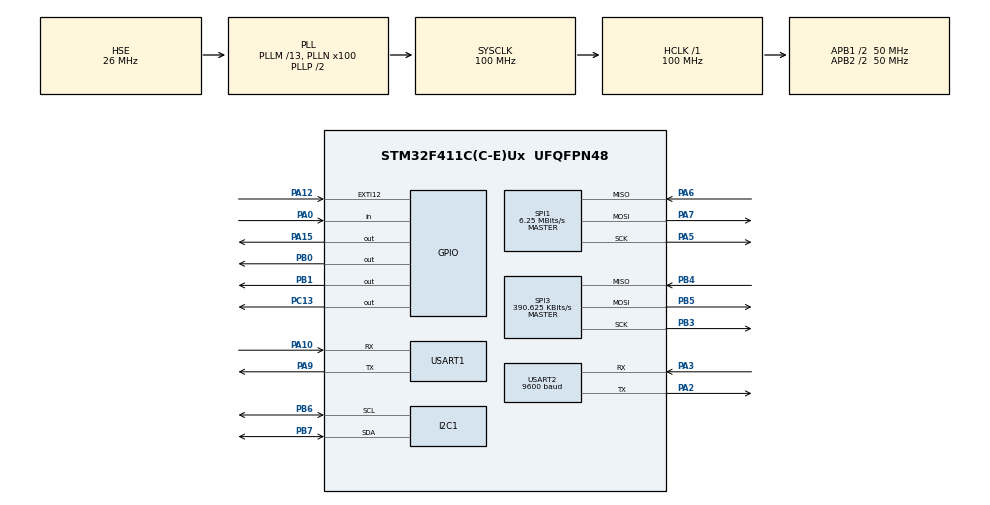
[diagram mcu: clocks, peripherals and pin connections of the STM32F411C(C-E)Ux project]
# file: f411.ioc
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Dma.Request0=USART2_RX
Dma.Request1=SPI3_TX
Dma.SPI3_TX.1.Direction=DMA_MEMORY_TO_PERIPH
Dma.SPI3_TX.1.FIFOMode=DMA_FIFOMODE_DISABLE
Dma.SPI3_TX.1.Instance=DMA1_Stream7
Dma.SPI3_TX.1.MemDataAlignment=DMA_MDATAALIGN_BYTE
Dma.SPI3_TX.1.MemInc=DMA_MINC_ENABLE
Dma.SPI3_TX.1.Mode=DMA_NORMAL
Dma.SPI3_TX.1.PeriphDataAlignment=DMA_PDATAALIGN_BYTE
Dma.SPI3_TX.1.PeriphInc=DMA_PINC_DISABLE
Dma.SPI3_TX.1.Priority=DMA_PRIORITY_MEDIUM
Dma.USART2_RX.0.Direction=DMA_PERIPH_TO_MEMORY
Dma.USART2_RX.0.FIFOMode=DMA_FIFOMODE_DISABLE
Dma.USART2_RX.0.Instance=DMA1_Stream5
Dma.USART2_RX.0.MemDataAlignment=DMA_MDATAALIGN_BYTE
Dma.USART2_RX.0.MemInc=DMA_MINC_ENABLE
Dma.USART2_RX.0.Mode=DMA_NORMAL
Dma.USART2_RX.0.PeriphDataAlignment=DMA_PDATAALIGN_BYTE
Dma.USART2_RX.0.PeriphInc=DMA_PINC_DISABLE
Dma.USART2_RX.0.Priority=DMA_PRIORITY_LOW
I2C1.I2C_Mode=I2C_Fast
Mcu.Family=STM32F4
Mcu.Name=STM32F411C(C-E)Ux
Mcu.Package=UFQFPN48
NVIC.DMA1_Stream5_IRQn=true\:0\:0\:false\:false\:true\:false\:true\:true
NVIC.DMA1_Stream7_IRQn=true\:0\:0\:false\:false\:true\:false\:true\:true
NVIC.EXTI15_10_IRQn=true\:0\:0\:false\:false\:true\:true\:true\:true
NVIC.PriorityGroup=NVIC_PRIORITYGROUP_4
NVIC.TIM3_IRQn=true\:0\:0\:false\:false\:true\:true\:true\:true
NVIC.USART2_IRQn=true\:0\:0\:false\:false\:true\:true\:true\:true
PA0-WKUP.Signal=GPIO_Input
PA10.Mode=Asynchronous
PA10.Signal=USART1_RX
PA12.GPIO_ModeDefaultEXTI=GPIO_MODE_IT_RISING
PA12.Signal=GPXTI12
PA13.Mode=Serial_Wire
PA13.Signal=SYS_JTMS-SWDIO
PA14.Mode=Serial_Wire
PA14.Signal=SYS_JTCK-SWCLK
PA15.GPIO_Speed=GPIO_SPEED_FREQ_VERY_HIGH
PA15.PinState=GPIO_PIN_SET
PA15.Signal=GPIO_Output
PA2.Mode=Asynchronous
PA2.Signal=USART2_TX
PA3.Mode=Asynchronous
PA3.Signal=USART2_RX
PA5.Mode=Full_Duplex_Master
PA5.Signal=SPI1_SCK
PA6.Mode=Full_Duplex_Master
PA6.Signal=SPI1_MISO
PA7.Mode=Full_Duplex_Master
PA7.Signal=SPI1_MOSI
PA9.Mode=Asynchronous
PA9.Signal=USART1_TX
PB0.Signal=GPIO_Output
PB1.Signal=GPIO_Output
PB3.Mode=Full_Duplex_Master
PB3.Signal=SPI3_SCK
PB4.Mode=Full_Duplex_Master
PB4.Signal=SPI3_MISO
PB5.Mode=Full_Duplex_Master
PB5.Signal=SPI3_MOSI
PB6.Mode=I2C
PB6.Signal=I2C1_SCL
PB7.Mode=I2C
PB7.Signal=I2C1_SDA
PC13-ANTI_TAMP.Signal=GPIO_Output
PH0\ -\ OSC_IN.Mode=HSE-External-Oscillator
PH0\ -\ OSC_IN.Signal=RCC_OSC_IN
PH1\ -\ OSC_OUT.Mode=HSE-External-Oscillator
PH1\ -\ OSC_OUT.Signal=RCC_OSC_OUT
ProjectManager.HeapSize=0x200
ProjectManager.StackSize=0x400
ProjectManager.TargetToolchain=STM32CubeIDE
RCC.48MHZClocksFreq_Value=50000000
RCC.AHBFreq_Value=100000000
RCC.APB1CLKDivider=RCC_HCLK_DIV2
RCC.APB1Freq_Value=50000000
RCC.APB1TimFreq_Value=100000000
RCC.APB2CLKDivider=RCC_HCLK_DIV2
RCC.APB2Freq_Value=50000000
RCC.APB2TimFreq_Value=100000000
RCC.CortexFreq_Value=100000000
RCC.HCLKFreq_Value=100000000
RCC.HSE_VALUE=26000000
RCC.HSI_VALUE=16000000
RCC.LSE_VALUE=32768
RCC.PLLM=13
RCC.PLLN=100
RCC.PLLSourceVirtual=RCC_PLLSOURCE_HSE
RCC.SYSCLKFreq_VALUE=100000000
RCC.SYSCLKSource=RCC_SYSCLKSOURCE_PLLCLK
RCC.VCOOutputFreq_Value=200000000
SPI1.BaudRatePrescaler=SPI_BAUDRATEPRESCALER_8
SPI1.CalculateBaudRate=6.25 MBits/s
SPI1.Direction=SPI_DIRECTION_2LINES
SPI1.Mode=SPI_MODE_MASTER
SPI1.VirtualType=VM_MASTER
SPI3.BaudRatePrescaler=SPI_BAUDRATEPRESCALER_128
SPI3.CLKPhase=SPI_PHASE_2EDGE
SPI3.CLKPolarity=SPI_POLARITY_HIGH
SPI3.CalculateBaudRate=390.625 KBits/s
SPI3.Direction=SPI_DIRECTION_2LINES
SPI3.Mode=SPI_MODE_MASTER
SPI3.VirtualType=VM_MASTER
TIM3.Period=1000-1
TIM3.Prescaler=72-1
USART1.VirtualMode=VM_ASYNC
USART2.BaudRate=9600
USART2.VirtualMode=VM_ASYNC
VP_TIM3_VS_ClockSourceINT.Mode=Internal
board=custom

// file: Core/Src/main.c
/* USER CODE BEGIN Header */
/**
  ******************************************************************************
  * @file           : main.c
  * @brief          : Main program body
  ******************************************************************************
  * @attention
  *
  * Copyright (c) 2022 STMicroelectronics.
  * All rights reserved.
  *
  * This software is licensed under terms that can be found in the LICENSE file
  * in the root directory of this software component.
  * If no LICENSE file comes with this software, it is provided AS-IS.
  *
  ******************************************************************************
  */
/* USER CODE END Header */
#include "main.h"

/* USER CODE BEGIN PM */
#include "stm32f4xx_hal_spi.h"

/* USER CODE END PM */

I2C_HandleTypeDef hi2c1;

SPI_HandleTypeDef hspi1;
SPI_HandleTypeDef hspi3;
DMA_HandleTypeDef hdma_spi3_tx;

TIM_HandleTypeDef htim3;

UART_HandleTypeDef huart1;
UART_HandleTypeDef huart2;
DMA_HandleTypeDef hdma_usart2_rx;

void SystemClock_Config(void);
static void MX_GPIO_Init(void);
static void MX_DMA_Init(void);
static void MX_USART1_UART_Init(void);
static void MX_I2C1_Init(void);
static void MX_USART2_UART_Init(void);
static void MX_SPI1_Init(void);
static void MX_SPI3_Init(void);
static void MX_TIM3_Init(void);

int main(void)
{

  /* MCU Configuration--------------------------------------------------------*/

  /* Reset of all peripherals, Initializes the Flash interface and the Systick. */
  HAL_Init();

  /* Configure the system clock */
  SystemClock_Config();

  /* Initialize all configured peripherals */
  MX_GPIO_Init();
  MX_DMA_Init();
  MX_USART1_UART_Init();
  MX_I2C1_Init();
  MX_USART2_UART_Init();
  MX_SPI1_Init();
  MX_SPI3_Init();
  MX_TIM3_Init();

  /* Infinite loop */
  while (1)
  {

  }
}

void SystemClock_Config(void)
{
  RCC_OscInitTypeDef RCC_OscInitStruct = {0};
  RCC_ClkInitTypeDef RCC_ClkInitStruct = {0};

  /** Configure the main internal regulator output voltage
  */
  __HAL_RCC_PWR_CLK_ENABLE();
  __HAL_PWR_VOLTAGESCALING_CONFIG(PWR_REGULATOR_VOLTAGE_SCALE1);

  /** Initializes the RCC Oscillators according to the specified parameters
  * in the RCC_OscInitTypeDef structure.
  */
  RCC_OscInitStruct.OscillatorType = RCC_OSCILLATORTYPE_HSE;
  RCC_OscInitStruct.HSEState = RCC_HSE_ON;
  RCC_OscInitStruct.PLL.PLLState = RCC_PLL_ON;
  RCC_OscInitStruct.PLL.PLLSource = RCC_PLLSOURCE_HSE;
  RCC_OscInitStruct.PLL.PLLM = 13;
  RCC_OscInitStruct.PLL.PLLN = 100;
  RCC_OscInitStruct.PLL.PLLP = RCC_PLLP_DIV2;
  RCC_OscInitStruct.PLL.PLLQ = 4;
  if (HAL_RCC_OscConfig(&RCC_OscInitStruct) != HAL_OK)
  {
    Error_Handler();
  }

  /** Initializes the CPU, AHB and APB buses clocks
  */
  RCC_ClkInitStruct.ClockType = RCC_CLOCKTYPE_HCLK|RCC_CLOCKTYPE_SYSCLK
                              |RCC_CLOCKTYPE_PCLK1|RCC_CLOCKTYPE_PCLK2;
  RCC_ClkInitStruct.SYSCLKSource = RCC_SYSCLKSOURCE_PLLCLK;
  RCC_ClkInitStruct.AHBCLKDivider = RCC_SYSCLK_DIV1;
  RCC_ClkInitStruct.APB1CLKDivider = RCC_HCLK_DIV2;
  RCC_ClkInitStruct.APB2CLKDivider = RCC_HCLK_DIV2;

  if (HAL_RCC_ClockConfig(&RCC_ClkInitStruct, FLASH_LATENCY_3) != HAL_OK)
  {
    Error_Handler();
  }
}

static void MX_I2C1_Init(void)
{

  hi2c1.Instance = I2C1;
  hi2c1.Init.ClockSpeed = 400000;
  hi2c1.Init.DutyCycle = I2C_DUTYCYCLE_2;
  hi2c1.Init.OwnAddress1 = 0;
  hi2c1.Init.AddressingMode = I2C_ADDRESSINGMODE_7BIT;
  hi2c1.Init.DualAddressMode = I2C_DUALADDRESS_DISABLE;
  hi2c1.Init.OwnAddress2 = 0;
  hi2c1.Init.GeneralCallMode = I2C_GENERALCALL_DISABLE;
  hi2c1.Init.NoStretchMode = I2C_NOSTRETCH_DISABLE;
  if (HAL_I2C_Init(&hi2c1) != HAL_OK)
  {
    Error_Handler();
  }

}

static void MX_SPI1_Init(void)
{

  /* SPI1 parameter configuration*/
  hspi1.Instance = SPI1;
  hspi1.Init.Mode = SPI_MODE_MASTER;
  hspi1.Init.Direction = SPI_DIRECTION_2LINES;
  hspi1.Init.DataSize = SPI_DATASIZE_8BIT;
  hspi1.Init.CLKPolarity = SPI_POLARITY_LOW;
  hspi1.Init.CLKPhase = SPI_PHASE_1EDGE;
  hspi1.Init.NSS = SPI_NSS_SOFT;
  hspi1.Init.BaudRatePrescaler = SPI_BAUDRATEPRESCALER_8;
  hspi1.Init.FirstBit = SPI_FIRSTBIT_MSB;
  hspi1.Init.TIMode = SPI_TIMODE_DISABLE;
  hspi1.Init.CRCCalculation = SPI_CRCCALCULATION_DISABLE;
  hspi1.Init.CRCPolynomial = 10;
  if (HAL_SPI_Init(&hspi1) != HAL_OK)
  {
    Error_Handler();
  }

}

static void MX_SPI3_Init(void)
{

  /* SPI3 parameter configuration*/
  hspi3.Instance = SPI3;
  hspi3.Init.Mode = SPI_MODE_MASTER;
  hspi3.Init.Direction = SPI_DIRECTION_2LINES;
  hspi3.Init.DataSize = SPI_DATASIZE_8BIT;
  hspi3.Init.CLKPolarity = SPI_POLARITY_HIGH;
  hspi3.Init.CLKPhase = SPI_PHASE_2EDGE;
  hspi3.Init.NSS = SPI_NSS_SOFT;
  hspi3.Init.BaudRatePrescaler = SPI_BAUDRATEPRESCALER_128;
  hspi3.Init.FirstBit = SPI_FIRSTBIT_MSB;
  hspi3.Init.TIMode = SPI_TIMODE_DISABLE;
  hspi3.Init.CRCCalculation = SPI_CRCCALCULATION_DISABLE;
  hspi3.Init.CRCPolynomial = 10;
  if (HAL_SPI_Init(&hspi3) != HAL_OK)
  {
    Error_Handler();
  }

}

static void MX_TIM3_Init(void)
{

  TIM_ClockConfigTypeDef sClockSourceConfig = {0};
  TIM_MasterConfigTypeDef sMasterConfig = {0};

  htim3.Instance = TIM3;
  htim3.Init.Prescaler = 72-1;
  htim3.Init.CounterMode = TIM_COUNTERMODE_UP;
  htim3.Init.Period = 1000-1;
  htim3.Init.ClockDivision = TIM_CLOCKDIVISION_DIV1;
  htim3.Init.AutoReloadPreload = TIM_AUTORELOAD_PRELOAD_DISABLE;
  if (HAL_TIM_Base_Init(&htim3) != HAL_OK)
  {
    Error_Handler();
  }
  sClockSourceConfig.ClockSource = TIM_CLOCKSOURCE_INTERNAL;
  if (HAL_TIM_ConfigClockSource(&htim3, &sClockSourceConfig) != HAL_OK)
  {
    Error_Handler();
  }
  sMasterConfig.MasterOutputTrigger = TIM_TRGO_RESET;
  sMasterConfig.MasterSlaveMode = TIM_MASTERSLAVEMODE_DISABLE;
  if (HAL_TIMEx_MasterConfigSynchronization(&htim3, &sMasterConfig) != HAL_OK)
  {
    Error_Handler();
  }

}

static void MX_USART1_UART_Init(void)
{

  huart1.Instance = USART1;
  huart1.Init.BaudRate = 115200;
  huart1.Init.WordLength = UART_WORDLENGTH_8B;
  huart1.Init.StopBits = UART_STOPBITS_1;
  huart1.Init.Parity = UART_PARITY_NONE;
  huart1.Init.Mode = UART_MODE_TX_RX;
  huart1.Init.HwFlowCtl = UART_HWCONTROL_NONE;
  huart1.Init.OverSampling = UART_OVERSAMPLING_16;
  if (HAL_UART_Init(&huart1) != HAL_OK)
  {
    Error_Handler();
  }

}

static void MX_USART2_UART_Init(void)
{

  huart2.Instance = USART2;
  huart2.Init.BaudRate = 9600;
  huart2.Init.WordLength = UART_WORDLENGTH_8B;
  huart2.Init.StopBits = UART_STOPBITS_1;
  huart2.Init.Parity = UART_PARITY_NONE;
  huart2.Init.Mode = UART_MODE_TX_RX;
  huart2.Init.HwFlowCtl = UART_HWCONTROL_NONE;
  huart2.Init.OverSampling = UART_OVERSAMPLING_16;
  if (HAL_UART_Init(&huart2) != HAL_OK)
  {
    Error_Handler();
  }

}

static void MX_DMA_Init(void)
{

  /* DMA controller clock enable */
  __HAL_RCC_DMA1_CLK_ENABLE();

  /* DMA interrupt init */
  /* DMA1_Stream5_IRQn interrupt configuration */
  HAL_NVIC_SetPriority(DMA1_Stream5_IRQn, 0, 0);
  HAL_NVIC_EnableIRQ(DMA1_Stream5_IRQn);
  /* DMA1_Stream7_IRQn interrupt configuration */
  HAL_NVIC_SetPriority(DMA1_Stream7_IRQn, 0, 0);
  HAL_NVIC_EnableIRQ(DMA1_Stream7_IRQn);

}

static void MX_GPIO_Init(void)
{
  GPIO_InitTypeDef GPIO_InitStruct = {0};

  /* GPIO Ports Clock Enable */
  __HAL_RCC_GPIOC_CLK_ENABLE();
  __HAL_RCC_GPIOH_CLK_ENABLE();
  __HAL_RCC_GPIOA_CLK_ENABLE();
  __HAL_RCC_GPIOB_CLK_ENABLE();

  /*Configure GPIO pin Output Level */
  HAL_GPIO_WritePin(GPIOC, GPIO_PIN_13, GPIO_PIN_RESET);

  /*Configure GPIO pin Output Level */
  HAL_GPIO_WritePin(GPIOB, GPIO_PIN_0|GPIO_PIN_1, GPIO_PIN_RESET);

  /*Configure GPIO pin Output Level */
  HAL_GPIO_WritePin(GPIOA, GPIO_PIN_15, GPIO_PIN_SET);

  /*Configure GPIO pin : PC13 */
  GPIO_InitStruct.Pin = GPIO_PIN_13;
  GPIO_InitStruct.Mode = GPIO_MODE_OUTPUT_PP;
  GPIO_InitStruct.Pull = GPIO_NOPULL;
  GPIO_InitStruct.Speed = GPIO_SPEED_FREQ_LOW;
  HAL_GPIO_Init(GPIOC, &GPIO_InitStruct);

  /*Configure GPIO pin : PA0 */
  GPIO_InitStruct.Pin = GPIO_PIN_0;
  GPIO_InitStruct.Mode = GPIO_MODE_INPUT;
  GPIO_InitStruct.Pull = GPIO_NOPULL;
  HAL_GPIO_Init(GPIOA, &GPIO_InitStruct);

  /*Configure GPIO pins : PB0 PB1 */
  GPIO_InitStruct.Pin = GPIO_PIN_0|GPIO_PIN_1;
  GPIO_InitStruct.Mode = GPIO_MODE_OUTPUT_PP;
  GPIO_InitStruct.Pull = GPIO_NOPULL;
  GPIO_InitStruct.Speed = GPIO_SPEED_FREQ_LOW;
  HAL_GPIO_Init(GPIOB, &GPIO_InitStruct);

  /*Configure GPIO pin : PA12 */
  GPIO_InitStruct.Pin = GPIO_PIN_12;
  GPIO_InitStruct.Mode = GPIO_MODE_IT_RISING;
  GPIO_InitStruct.Pull = GPIO_NOPULL;
  HAL_GPIO_Init(GPIOA, &GPIO_InitStruct);

  /*Configure GPIO pin : PA15 */
  GPIO_InitStruct.Pin = GPIO_PIN_15;
  GPIO_InitStruct.Mode = GPIO_MODE_OUTPUT_PP;
  GPIO_InitStruct.Pull = GPIO_NOPULL;
  GPIO_InitStruct.Speed = GPIO_SPEED_FREQ_VERY_HIGH;
  HAL_GPIO_Init(GPIOA, &GPIO_InitStruct);

  /* EXTI interrupt init*/
  HAL_NVIC_SetPriority(EXTI15_10_IRQn, 0, 0);
  HAL_NVIC_EnableIRQ(EXTI15_10_IRQn);

}

void Error_Handler(void)
{
  __disable_irq();
  while (1)
  {
  }
}
